# RTS5918 register map
Vendor: Realtek Semiconductor Corp.; Series: RTS5918 Series; File version: 1.00
CPU: ARMV8MML r0p0, little endian, MPU, FPU, VTOR, 3 interrupt priority bits, 8 SAU regions
Registers are 32-bit, read-write, reset 0x0 unless marked. A register's access mark holds for its fields unless they carry their own. Offsets are from the block's base; [hi:lo] are bit positions; {n}, {i} and the like mark numbered series; 'fields as' and 'values as' point back to an identical list.

## SPIS — SPIS Controller
Base 0x40222000
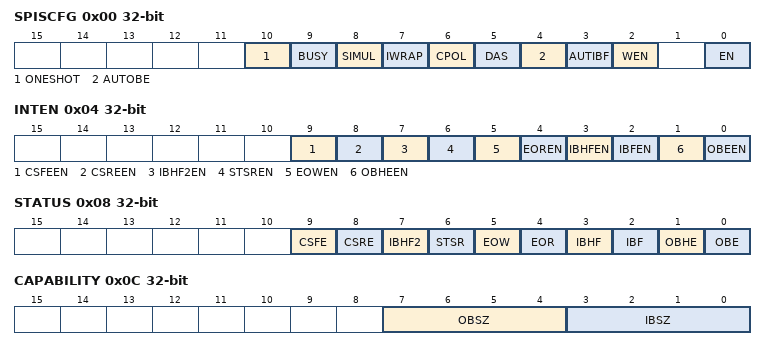
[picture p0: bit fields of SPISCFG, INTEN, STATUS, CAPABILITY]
0x00 SPISCFG — SPIS CONFIGURATION REGISTER
  [10] ONESHOT — Write One Shot Enable Bit
    0=DISABLE (WEN is Not Affected by Write Transactions); 1=ENABLE (WEN is Cleared At End of Write Transaction)
  [9] BUSY ro — SPIS Busy Bit
  [8] SIMUL — Simultaneous Read/Write Enable Bit
    0=DISABLE (Disable Simultaneous Read/Write); 1=ENABLE (Enable Simultaneous Read/Write)
  [7] IWRAP — Input Buffer Wrap-Around Enable Bit
    0=DISABLE (No Input Buffer Wrapping); 1=ENABLE (Wrap Input Buffer to the First Address)
  [6] CPOL — Clock Polarity Sample Bit
    0=RISING (Rising Sample, Falling Ouput); 1=FALLING (Faliing Sample, Rising Ouput)
  [5] DAS — Data After Satatus Enable Bit
    0=DISABLE (Disable Data After Satatus); 1=ENABLE (Enable Data After Satatus)
  [4] AUTOBE — Auto Output Buffer Empty Indication Enable Bit
    0=MANUAL (Manual Update the OBES bit in DEVSTS register); 1=AUTO (Auto Update the OBES bit in DEVSTS register)
  [3] AUTIBF — Auto Input Buffer Full Indication Enable Bit
    0=MANUAL (Manual Update the IBFS bit in DEVSTS register); 1=AUTO (Auto Update the IBFS bit in DEVSTS register)
  [2] WEN — Write to Input Buffer Enable Bit
    0=DISABLE (Disable Write to Input Buffer); 1=ENABLE (Enable Write to Input Buffer)
  [0] EN — SPIS Enable Bit
    0=DISABLE (Disable SPIS); 1=ENABLE (Enable SPIS)
0x04 INTEN — INTERRUPT ENABLE REGISTER
  [9] CSFEEN — CS# Falling Edge Interrupt Enable
    0=DISABLE (Disable CS# Falling Edge Interrupt); 1=ENABLE (Enable CS# Falling Edge Interrupt)
  [8] CSREEN — CS# Rising Edge Interrupt Enable
    0=DISABLE (Disable CS# Rising Edge Interrupt); 1=ENABLE (Enable CS# Rising Edge Interrupt)
  [7] IBHF2EN — Input Buffer Half Full 2 Interrupt Enable
    0=DISABLE (Disable Input Buffer Half Full 2 Interrupt); 1=ENABLE (Enable Input Buffer Half Full 2 Interrupt)
  [6] STSREN — Status Read Interrupt Enable
    0=DISABLE (Disable Status Read Interrupt); 1=ENABLE (Enable Status Read Interrupt)
  [5] EOWEN — End-of-Data for Write Transaction Interrupt Enable
    0=DISABLE (Disable End-of-Data for Write Transaction Interrupt); 1=ENABLE (Enable End-of-Data for Write Transaction Interrupt)
  [4] EOREN — End-of-Data for Read Transaction Interrupt Enable
    0=DISABLE (Disable End-of-Data for Read Transaction Interrupt); 1=ENABLE (Enable End-of-Data for Read Transaction Interrupt)
  [3] IBHFEN — Input Buffer Half Full Interrupt Enable
    0=DISABLE (Disable Input Buffer Half Full Interrupt); 1=ENABLE (Enable Input Buffer Half Full Interrupt)
  [2] IBFEN — Input Buffer Full Interrupt Enable
    0=DISABLE (Disable Input Buffer Full Interrupt); 1=ENABLE (Enable Input Buffer Full Interrupt)
  [1] OBHEEN — Output Buffer Half Empty Interrupt Enable
    0=DISABLE (Disable Output Buffer Half Empty Interrupt); 1=ENABLE (Enable Output Buffer Half Empty Interrupt)
  [0] OBEEN — Output Buffer Empty Interrupt Enable
    0=DISABLE (Disable Output Buffer Empty Interrupt); 1=ENABLE (Enable Output Buffer Empty Interrupt)
0x08 STATUS
  [9] CSFE read-clears — CS# Falling Edge
    0=None (No CS# Falling Edge); 1=CLEAR (Clear CS# Falling Edge)
  [8] CSRE read-clears — CS# Rising Edge
    0=None (No CS# Rising Edge); 1=CLEAR (Clear CS# Rising Edge)
  [7] IBHF2 read-clears — Input Buffe Half Full 2
    0=None (No Input Buffe Half Full); 1=CLEAR (Clear Input Buffe Half Full)
  [6] STSR read-clears — Device Status Read
    0=None (No Device Status Read); 1=CLEAR (Clear Device Status Read)
  [5] EOW read-clears — End-of-Data for Write Transaction
    0=None (No End-of-Data for Write Transaction); 1=CLEAR (Clear End-of-Data for Write Transaction)
  [4] EOR read-clears — End-of-Data for Read Transaction
    0=None (No End-of-Data for Read Transaction); 1=CLEAR (Clear End-of-Data for Read Transaction)
  [3] IBHF read-clears — Input Buffer Half Full
    0=Normal operation; 1=HALF_FULL (Input buffer is half full or input buffer level reached)
  [2] IBF read-clears — Input Buffer Full
    0=Normal operation; 1=FULL (Input buffer is full or input buffer level reached)
  [1] OBHE read-clears — Output Buffer Half Empty
    0=Normal operation; 1=HALF_EMPTY (Output buffer is half empty or output buffer level reached)
  [0] OBE read-clears — Output Buffer Empty
    0=None (Output Buffer not Empty); 1=CLEAR (Clear Output Buffer not Empty)
0x0C CAPABILITY ro — ADDRESS REGISTER
  [7:4] OBSZ — Output Buffer Size
  [3:0] IBSZ — Input Buffer Size
0x10 IBFPTR ro — INPUT BUFFER POINTER REGISTER
  [7:0] IBFPTR — Input Buffer Pointer
0x14 OBFPTR ro — OUTPUT BUFFER POINTER REGISTER
  [7:0] OBFPTR — Output Buffer Pointer
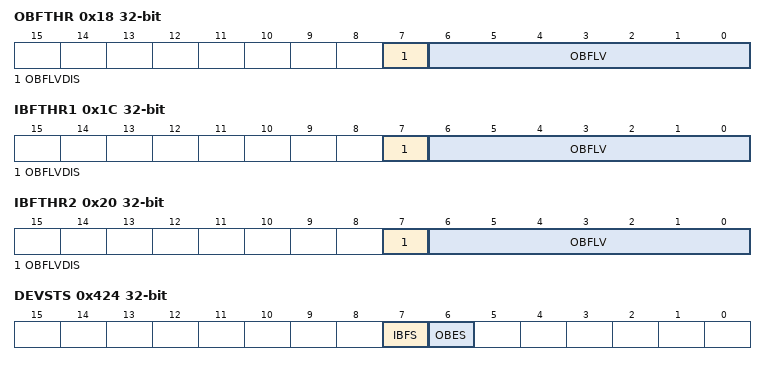
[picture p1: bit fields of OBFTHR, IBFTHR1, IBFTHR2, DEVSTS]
0x18 OBFTHR — OUTPUT BUFFER THRESHOLD REGISTER
  [7] OBFLVDIS — Threshold Disable Bit
    0=ENABLE (Enable Threshold Level); 1=DISABLE (Dis Threshold Level)
  [6:0] OBFLV — Output Buffer Level
0x1C IBFTHR1 — OUTPUT BUFFER THRESHOLD REGISTER
  fields as OBFTHR
0x20 IBFTHR2 — OUTPUT BUFFER THRESHOLD REGISTER
  fields as OBFTHR
{0x24+4i} IBF[{i}] (i=0..127) ro — INPUT BUFFER REGISTER
{0x224+4i} OBF[{i}] (i=0..127) — OUTPUT BUFFER REGISTER
0x424 DEVSTS — DEVICE STATUS REGISTER
  [7] IBFS — Input Buffer Full Bit
    0=CLEAR (Clear Input Buffer Full Status); 1=ENABLE (Input Buffer Full Status)
  [6] OBES — Output Buffer Empty Bit
    0=CLEAR (Clear Output Buffer Empty Status); 1=ENABLE (Output Buffer Empty Status)
